# N32G430 register map
Vendor: Nationstech Ltd.; File version: 1.0
Registers are 32-bit, read-write, reset 0x0 unless marked. A register's access mark holds for its fields unless they carry their own. Offsets are from the block's base; [hi:lo] are bit positions; {n}, {i} and the like mark numbered series.

## AFIO — Alternate function I/O
Base 0x40010000
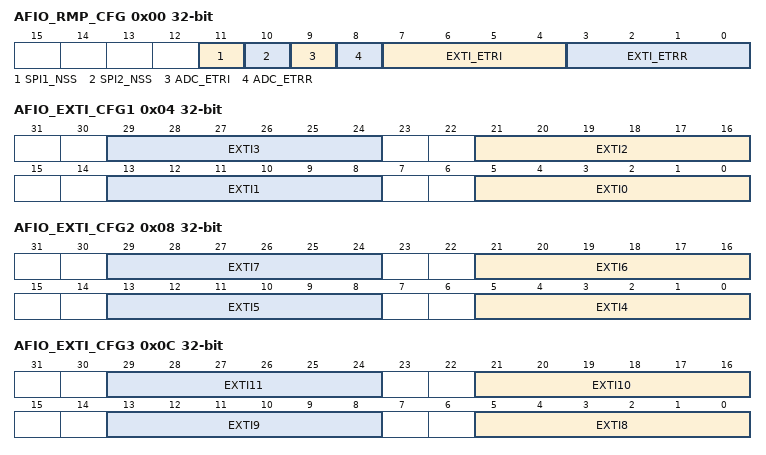
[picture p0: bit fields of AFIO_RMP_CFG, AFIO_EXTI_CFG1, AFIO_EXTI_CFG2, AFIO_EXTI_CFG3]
0x00 AFIO_RMP_CFG
  [11] SPI1_NSS, [10] SPI2_NSS, [9] ADC_ETRI, [8] ADC_ETRR, [7:4] EXTI_ETRI, [3:0] EXTI_ETRR
0x04 AFIO_EXTI_CFG1 (reset mask 0x3333)
  [8n+5:8n] EXTI{n} (n=0..3)
0x08 AFIO_EXTI_CFG2 (reset mask 0x3333)
  [8n-27:8n-32] EXTI{n} (n=4..7)
0x0C AFIO_EXTI_CFG3 (reset mask 0x3333)
  [8n-59:8n-64] EXTI{n} (n=8..11)
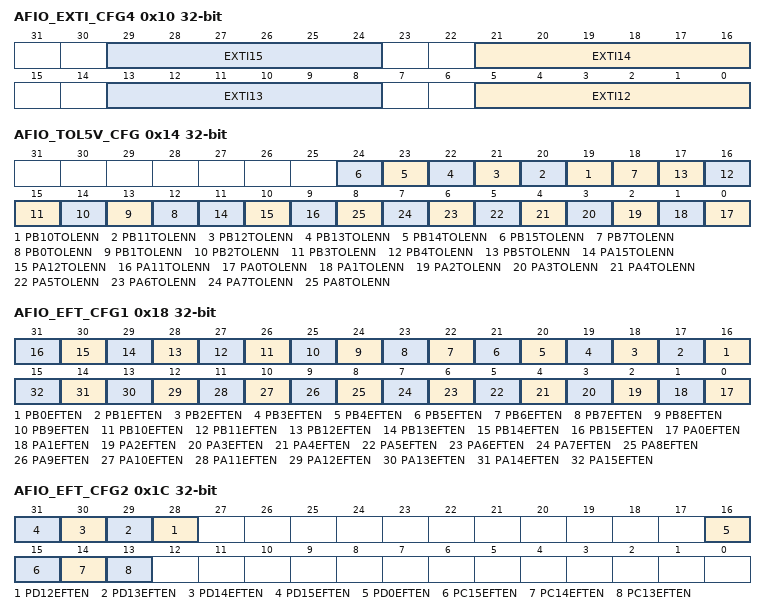
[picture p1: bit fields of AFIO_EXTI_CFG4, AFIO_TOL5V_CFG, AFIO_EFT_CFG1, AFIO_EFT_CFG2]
0x10 AFIO_EXTI_CFG4 (reset mask 0x3333)
  [8n-91:8n-96] EXTI{n} (n=12..15)
0x14 AFIO_TOL5V_CFG
  [n+9] PB{n}TOLENN (n=10..15), [18] PB7TOLENN, [n+12] PB{n}TOLENN (n=0..5), [11] PA15TOLENN, [10] PA12TOLENN, [9] PA11TOLENN, [n] PA{n}TOLENN (n=0..8)
0x18 AFIO_EFT_CFG1
  [n+16] PB{n}EFTEN (n=0..15), [n] PA{n}EFTEN (n=0..15)
0x1C AFIO_EFT_CFG2
  [n+16] PD{n}EFTEN (n=12..15), [16] PD0EFTEN, [15] PC15EFTEN, [14] PC14EFTEN, [13] PC13EFTEN
0x20 AFIO_FILT_CFG
  [4:0] IOFILTCFG
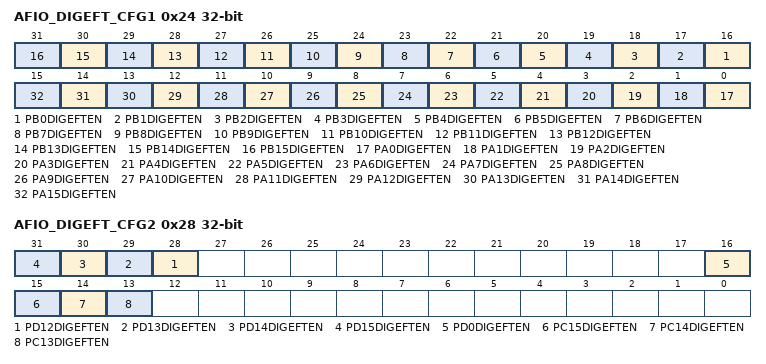
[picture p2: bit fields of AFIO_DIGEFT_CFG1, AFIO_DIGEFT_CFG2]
0x24 AFIO_DIGEFT_CFG1
  [n+16] PB{n}DIGEFTEN (n=0..15), [n] PA{n}DIGEFTEN (n=0..15)
0x28 AFIO_DIGEFT_CFG2
  [n+16] PD{n}DIGEFTEN (n=12..15), [16] PD0DIGEFTEN, [15] PC15DIGEFTEN, [14] PC14DIGEFTEN, [13] PC13DIGEFTEN

## I2C1 — Inter integrated circuit
Base 0x40005400
Same registers: I2C2 0x40005800
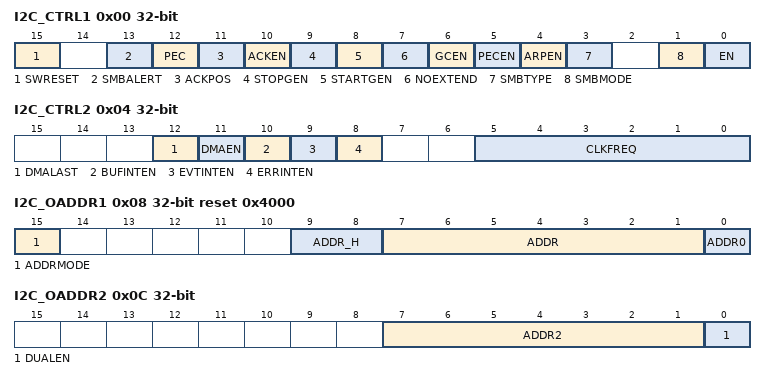
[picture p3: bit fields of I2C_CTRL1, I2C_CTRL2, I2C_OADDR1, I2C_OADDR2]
0x00 I2C_CTRL1
  [15] SWRESET, [13] SMBALERT, [12] PEC, [11] ACKPOS, [10] ACKEN, [9] STOPGEN, [8] STARTGEN, [7] NOEXTEND, [6] GCEN, [5] PECEN, [4] ARPEN, [3] SMBTYPE, [1] SMBMODE, [0] EN
0x04 I2C_CTRL2
  [12] DMALAST, [11] DMAEN, [10] BUFINTEN, [9] EVTINTEN, [8] ERRINTEN, [5:0] CLKFREQ
0x08 I2C_OADDR1 reset 0x4000
  [15] ADDRMODE, [9:8] ADDR_H, [7:1] ADDR, [0] ADDR0
0x0C I2C_OADDR2
  [7:1] ADDR2, [0] DUALEN
0x10 I2C_DAT
  [7:0] DATA
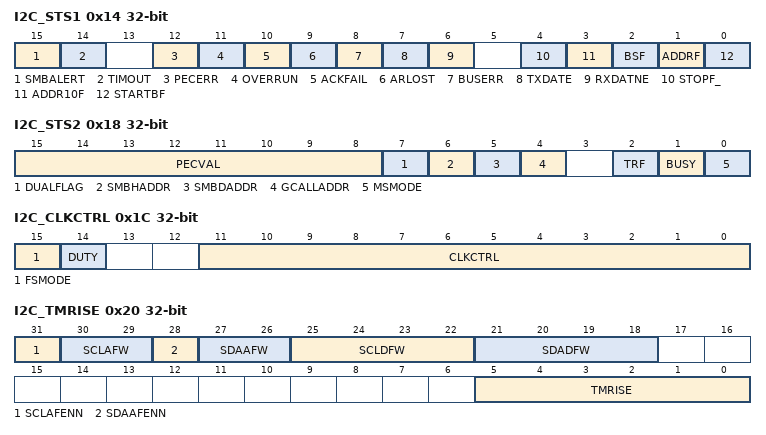
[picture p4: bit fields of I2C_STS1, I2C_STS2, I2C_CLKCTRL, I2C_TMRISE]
0x14 I2C_STS1
  [15] SMBALERT, [14] TIMOUT, [12] PECERR, [11] OVERRUN, [10] ACKFAIL, [9] ARLOST, [8] BUSERR, [7] TXDATE, [6] RXDATNE, [4] STOPF_, [3] ADDR10F, [2] BSF, [1] ADDRF, [0] STARTBF
0x18 I2C_STS2
  [15:8] PECVAL, [7] DUALFLAG, [6] SMBHADDR, [5] SMBDADDR, [4] GCALLADDR, [2] TRF, [1] BUSY, [0] MSMODE
0x1C I2C_CLKCTRL
  [15] FSMODE, [14] DUTY, [11:0] CLKCTRL
0x20 I2C_TMRISE
  [31] SCLAFENN, [30:29] SCLAFW, [28] SDAAFENN, [27:26] SDAAFW, [25:22] SCLDFW, [21:18] SDADFW, [5:0] TMRISE

## IWDG — Independent watchdog
Base 0x40003000
0x00 IWDG_KEY
  [15:0] KEYV
0x04 IWDG_PREDIV
  [2:0] PD
0x08 IWDG_RELV reset 0xFFF
  [11:0] REL
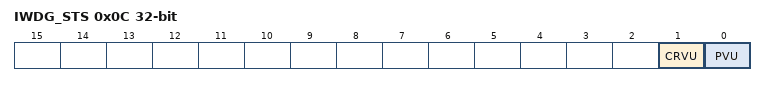
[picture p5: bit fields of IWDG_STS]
0x0C IWDG_STS
  [1] CRVU, [0] PVU

## BEEPER — Beeper unit
Base 0x40010800
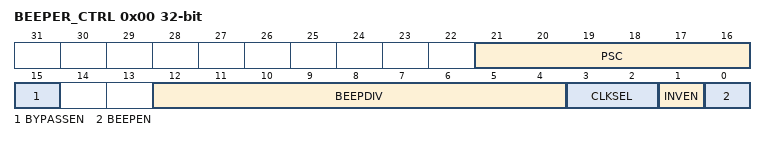
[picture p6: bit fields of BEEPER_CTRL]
0x00 BEEPER_CTRL (reset mask 0x3FFF)
  [21:16] PSC, [15] BYPASSEN, [12:4] BEEPDIV, [3:2] CLKSEL, [1] INVEN, [0] BEEPEN

## LPTIM — Low power timer control
Base 0x40004C00
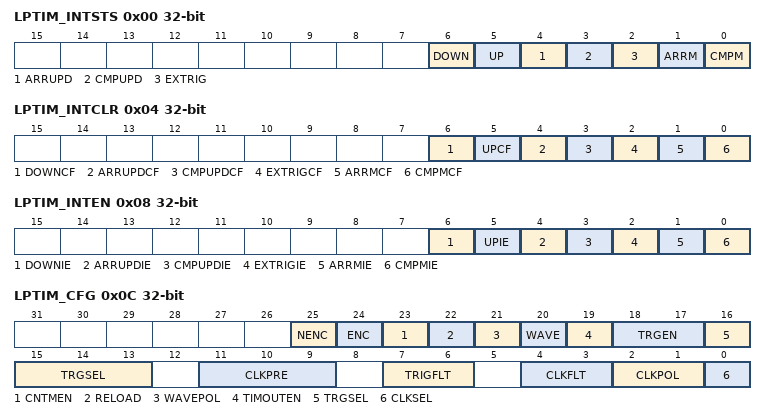
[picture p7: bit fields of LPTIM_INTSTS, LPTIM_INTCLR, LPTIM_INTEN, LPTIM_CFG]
0x00 LPTIM_INTSTS read
  [6] DOWN, [5] UP, [4] ARRUPD, [3] CMPUPD, [2] EXTRIG, [1] ARRM, [0] CMPM
0x04 LPTIM_INTCLR write
  [6] DOWNCF, [5] UPCF, [4] ARRUPDCF, [3] CMPUPDCF, [2] EXTRIGCF, [1] ARRMCF, [0] CMPMCF
0x08 LPTIM_INTEN
  [6] DOWNIE, [5] UPIE, [4] ARRUPDIE, [3] CMPUPDIE, [2] EXTRIGIE, [1] ARRMIE, [0] CMPMIE
0x0C LPTIM_CFG (reset mask 0x3FEEEEF)
  [25] NENC, [24] ENC, [23] CNTMEN, [22] RELOAD, [21] WAVEPOL, [20] WAVE, [19] TIMOUTEN, [18:17] TRGEN, [16:13] TRGSEL, [11:9] CLKPRE, [7:6] TRIGFLT, [4:3] CLKFLT, [2:1] CLKPOL, [0] CLKSEL
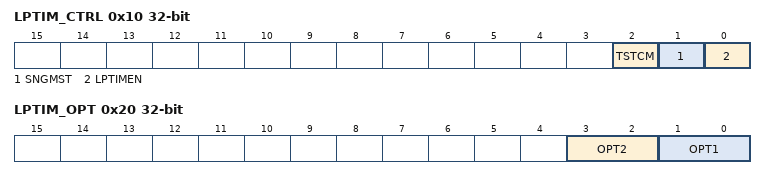
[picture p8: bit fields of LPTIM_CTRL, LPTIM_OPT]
0x10 LPTIM_CTRL
  [2] TSTCM, [1] SNGMST, [0] LPTIMEN
0x14 LPTIM_CMP
  [15:0] CMPVAL
0x18 LPTIM_ARR reset 0x1
  [15:0] ARRVAL
0x1C LPTIM_CNT reset 0x1
  [15:0] CNTVAL
0x20 LPTIM_OPT
  [3:2] OPT2, [1:0] OPT1

## PWR — Power control
Base 0x40007000
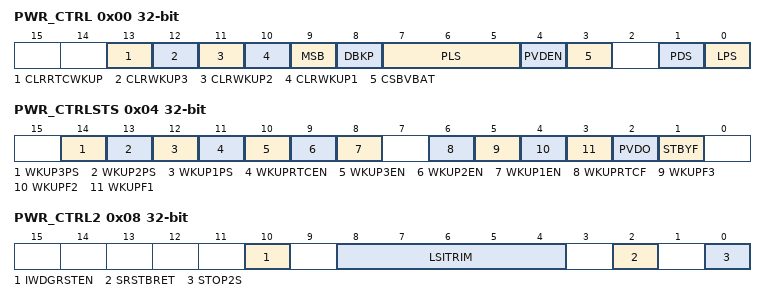
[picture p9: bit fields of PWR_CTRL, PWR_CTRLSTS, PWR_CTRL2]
0x00 PWR_CTRL
  [13] CLRRTCWKUP, [12] CLRWKUP3, [11] CLRWKUP2, [10] CLRWKUP1, [9] MSB, [8] DBKP, [7:5] PLS, [4] PVDEN, [3] CSBVBAT, [1] PDS, [0] LPS
0x04 PWR_CTRLSTS
  [14] WKUP3PS, [13] WKUP2PS, [12] WKUP1PS, [11] WKUPRTCEN, [10] WKUP3EN, [9] WKUP2EN, [8] WKUP1EN, [6] WKUPRTCF, [5] WKUPF3, [4] WKUPF2, [3] WKUPF1, [2] PVDO, [1] STBYF
0x08 PWR_CTRL2
  [10] IWDGRSTEN, [8:4] LSITRIM, [2] SRSTBRET, [0] STOP2S
